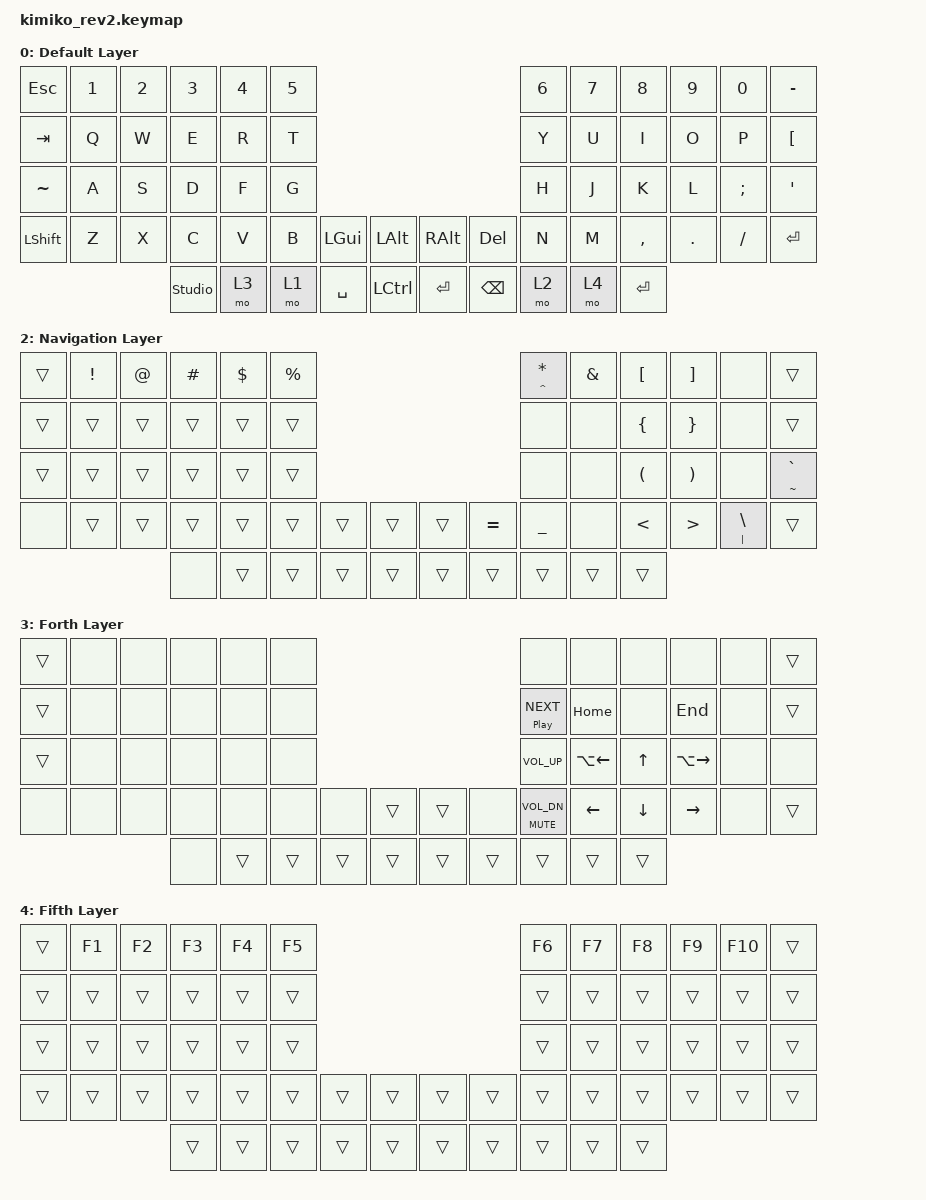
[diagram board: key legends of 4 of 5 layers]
// This file was generated from a template. Edit it to match your keyboard.
// See https://zmk.dev/docs/development/hardware-integration/new-shield for more instructions.

#include <behaviors.dtsi>
#include <dt-bindings/zmk/keys.h>
#include <dt-bindings/zmk/pointing.h>

/ {
    // Define a default keymap here.
    // See https://zmk.dev/docs/development/hardware-integration/new-shield#default-keymap.
    keymap {
        compatible = "zmk,keymap";

        default_layer {
            display-name = "Default Layer";
			bindings = <
				 &kp ESC        &kp N1        &kp N2        &kp N3        &kp N4        &kp N5                                                                          &kp N6        &kp N7        &kp N8        &kp N9        &kp N0        &kp MINUS
				 &kp TAB        &kp Q         &kp W         &kp E         &kp R         &kp T                                                                           &kp Y         &kp U         &kp I         &kp O         &kp P         &kp LBKT
				 &kp TILDE      &kp A         &kp S         &kp D         &kp F         &kp G                                                                           &kp H         &kp J         &kp K         &kp L         &kp SEMICOLON  &kp SQT
				 &kp LSHFT      &kp Z         &kp X         &kp C         &kp V         &kp B         &kp LGUI      &kp LALT             &kp RALT      &kp DEL          &kp N         &kp M         &kp COMMA     &kp DOT       &kp SLASH     &kp RET
				                                            &studio_unlock  &mo 3       &mo 1         &kp SPACE     &kp LCTRL            &kp ENTER     &kp BSPC         &mo 2         &mo 4         &kp ENTER
            >;
            sensor-bindings = <&inc_dec_kp C_VOL_UP C_VOL_DN &inc_dec_kp PG_UP PG_DN>;
        };
        
        num_layer {
            display-name = "Numpad Layer";
			bindings = <
				 &trans         &trans          &trans     &trans          &trans           &trans                                                                           &kp SLASH     &kp N7        &kp N8        &kp N9        &none           &trans
				 &trans         &none           &none      &none           &none           &none                                                                             &kp KP_N7     &kp KP_N7      &kp KP_N8        &kp KP_N9        &none           &trans
				 &trans         &none           &none      &none           &none           &none                                                                             &kp KP_DOT    &kp KP_N4      &kp KP_N5        &kp KP_N6        &none           &none
				 &none          &none           &none      &none           &none           &none             &none            &trans                     &trans              &kp KP_N0     &kp KP_N1      &kp KP_N2        &kp KP_N3        &trans           &trans
				                                           &trans          &trans           &trans           &trans           &trans                     &trans              &trans        &trans         &trans           &trans
			>;
            sensor-bindings = <&inc_dec_kp C_VOL_UP C_VOL_DN &inc_dec_kp PG_UP PG_DN>;
		};

		nav_layer {
            display-name = "Navigation Layer";
			bindings = <
				 &trans           &kp EXCL      &kp AT        &kp HASH      &kp DLLR      &kp PRCNT                                                                       &mt CARET ASTRK &kp AMPS    &kp LBKT      &kp RBKT      &none           &trans
				 &trans           &trans           &trans           &trans           &trans           &trans                                                                             &none           &none           &kp LBRC      &kp RBRC      &none           &trans
				 &trans           &trans           &trans           &trans           &trans           &trans                                                                             &none           &none           &kp LPAR      &kp RPAR      &none           &mt TILDE GRAVE
				 &none           &trans           &trans           &trans           &trans           &trans           &trans           &trans                     &trans           &kp EQUAL     &kp UNDER     &none           &kp LT        &kp GT        &mt PIPE BSLH &trans
				                                           &none           &trans           &trans           &trans           &trans                     &trans           &trans           &trans           &trans           &trans
			>;
            sensor-bindings = <&inc_dec_kp C_VOL_UP C_VOL_DN &inc_dec_kp PG_UP PG_DN>;
		};

		arrow_layer {
            display-name = "Forth Layer";
			bindings = <
				 &trans           &none           &none           &none           &none           &none                                                                             &none           &none           &none           &none           &none           &trans
				 &trans           &none           &none           &none           &none           &none                                                                             &mt C_PP C_NEXT &kp HOME    &none           &kp END       &none           &trans
				 &trans           &none           &none           &none           &none           &none                                                                             &kp C_VOL_UP  &kp LA(LEFT)  &kp UP        &kp LA(RIGHT) &none           &none
				 &none           &none           &none           &none           &none           &none           &none           &trans                     &trans           &none           &mt C_MUTE C_VOL_DN &kp LEFT &kp DOWN     &kp RIGHT     &none           &trans
				                                           &none           &trans           &trans           &trans           &trans                     &trans           &trans           &trans           &trans           &trans
			>;
            sensor-bindings = <&inc_dec_kp C_VOL_UP C_VOL_DN &inc_dec_kp PG_UP PG_DN>;
		};

		function_layer {
            display-name = "Fifth Layer";
			bindings = <
				 &trans           &kp F1        &kp F2        &kp F3        &kp F4        &kp F5                                                                          &kp F6        &kp F7        &kp F8        &kp F9        &kp F10       &trans
				 &trans           &trans           &trans           &trans           &trans           &trans                                                                             &trans           &trans           &trans           &trans           &trans           &trans
				 &trans           &trans           &trans           &trans           &trans           &trans                                                                             &trans           &trans           &trans           &trans           &trans           &trans
				 &trans           &trans           &trans           &trans           &trans           &trans           &trans           &trans                     &trans           &trans           &trans           &trans           &trans           &trans           &trans           &trans
				                                           &trans           &trans           &trans           &trans           &trans                     &trans           &trans           &trans           &trans           &trans
			>;
            sensor-bindings = <&inc_dec_kp C_VOL_UP C_VOL_DN &inc_dec_kp PG_UP PG_DN>;
		};
    };
};


/*

//#include <behaviors/num_word.dtsi>
//#include <dt-bindings/zmk/bt.h>

/ {
	behaviors {
		ht_tp: ht_tp {
			compatible = "zmk,behavior-hold-tap";
			#binding-cells = <2>;
			tapping-term-ms = <250>;
			quick-tap-ms = <0>;
			require-prior-idle-ms = <125>;
			flavor = "tap-preferred";
			bindings = <&kp>, <&kp>;
		};
	};
	keymap {
		compatible = "zmk,keymap";
		colemak_layer {
			bindings = <
				 &none           &kp N1        &kp N2        &kp N3        &kp N4        &kp N5                                                                          &kp N6        &kp N7        &kp N8        &kp N9        &kp N0        &kp DEL
				 &kp TAB       &kp Q         &kp W         &lt FUNC F    &kp P         &kp B                                                                           &kp J         &kp L         &kp U         &kp Y         &kp SEMICOLON &kp BSPC
				 &kp LCTRL     &kp A         &kp R         &kp S         &kp T         &kp G                                                                           &kp M         &kp N         &kp E         &kp I         &kp O         &kp SQT
				 &kp LSHFT     &kp Z         &kp X         &kp C         &kp D         &kp V         &none           &kp UP                  &kp LEFT      &none           &kp K         &kp H         &kp COMMA     &kp DOT       &kp SLASH     &kp ESC
				                                           &none           &kp LCMD      &mo SQUARE    &kp SPACE     &kp DOWN                &kp RIGHT     &lt ARROW RET &mo TRIANGLE  &kp RALT      &kp LG(LC(Q))
			>;
		};
	};
};

*/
